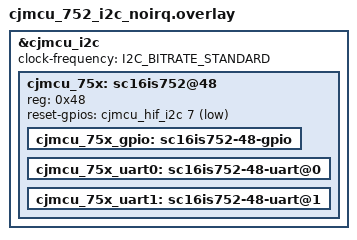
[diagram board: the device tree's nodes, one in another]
/*
 * Copyright (c) 2024 TiaC Systems
 * SPDX-License-Identifier: Apache-2.0
 */

#include <zephyr/dt-bindings/i2c/i2c.h>
#include <zephyr/dt-bindings/gpio/gpio.h>

&cjmcu_i2c {
	status = "okay";

	clock-frequency = <I2C_BITRATE_STANDARD>;

	cjmcu_75x: sc16is752@48 {
		reg = <0x48>;

		reset-gpios = <&cjmcu_hif_i2c 7 (GPIO_PULL_UP | GPIO_ACTIVE_LOW)>;

		cjmcu_75x_gpio: sc16is752-48-gpio {};
		cjmcu_75x_uart0: sc16is752-48-uart@0 {};
		cjmcu_75x_uart1: sc16is752-48-uart@1 {};
	};
};

#include "cjmcu_752.dtsi"
